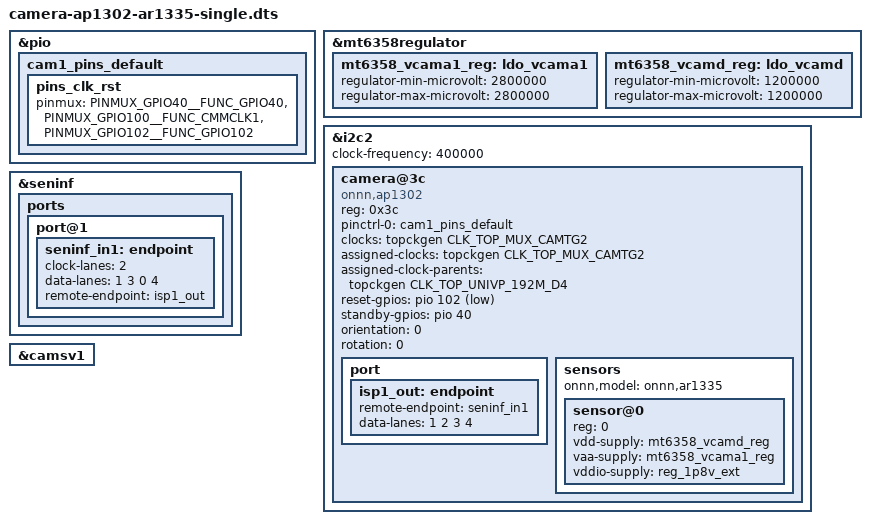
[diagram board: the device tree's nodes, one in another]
// SPDX-License-Identifier: GPL-2.0

#include <dt-bindings/clock/mt8183-clk.h>
#include <dt-bindings/gpio/gpio.h>
#include <dt-bindings/pinctrl/mt8183-pinfunc.h>

/dts-v1/;
/plugin/;

/ {
	fragment@0 {
		target = <&pio>;
		__overlay__ {
			cam1_pins_default: cam1_pins_default {
				pins_clk_rst {
					pinmux = <PINMUX_GPIO40__FUNC_GPIO40>,
						 <PINMUX_GPIO100__FUNC_CMMCLK1>,
						 <PINMUX_GPIO102__FUNC_GPIO102>;
				};
			};
		};
	};

	fragment@1 {
		target = <&mt6358regulator>;
		__overlay__ {
			mt6358_vcama1_reg: ldo_vcama1 {
				regulator-min-microvolt = <2800000>;
				regulator-max-microvolt = <2800000>;
			};

			mt6358_vcamd_reg: ldo_vcamd {
				regulator-min-microvolt = <1200000>;
				regulator-max-microvolt = <1200000>;
			};
		};
	};

	fragment@2 {
		target = <&i2c2>;
		__overlay__ {
			clock-frequency = <400000>;

			camera@3c {
				compatible = "onnn,ap1302";
				reg = <0x3c>;

				pinctrl-names = "default";
				pinctrl-0 = <&cam1_pins_default>;

				clocks = <&topckgen CLK_TOP_MUX_CAMTG2>;
				assigned-clocks = <&topckgen CLK_TOP_MUX_CAMTG2>;
				assigned-clock-parents = <&topckgen CLK_TOP_UNIVP_192M_D4>;

				reset-gpios = <&pio 102 GPIO_ACTIVE_LOW>;
				standby-gpios = <&pio 40 GPIO_ACTIVE_HIGH>;

				orientation = <0>;
				rotation = <0>;

				port {
					isp1_out: endpoint {
						remote-endpoint = <&seninf_in1>;
						data-lanes = <1 2 3 4>;
					};
				};

				sensors {
					#address-cells = <1>;
					#size-cells = <0>;

					onnn,model = "onnn,ar1335";

					sensor@0 {
						reg = <0>;

						vdd-supply = <&mt6358_vcamd_reg>;
						vaa-supply = <&mt6358_vcama1_reg>;
						vddio-supply = <&reg_1p8v_ext>;
					};
				};
			};
		};
	};

	fragment@3 {
		target = <&seninf>;
		__overlay__ {
			status = "okay";

			ports {
				port@1 {
					seninf_in1: endpoint {
						clock-lanes = <2>;
						data-lanes = <1 3 0 4>;
						remote-endpoint = <&isp1_out>;
					};
				};

			};
		};
	};

	fragment@4 {
		target = <&camsv1>;
		__overlay__ {
			status = "okay";
		};
	};
};
